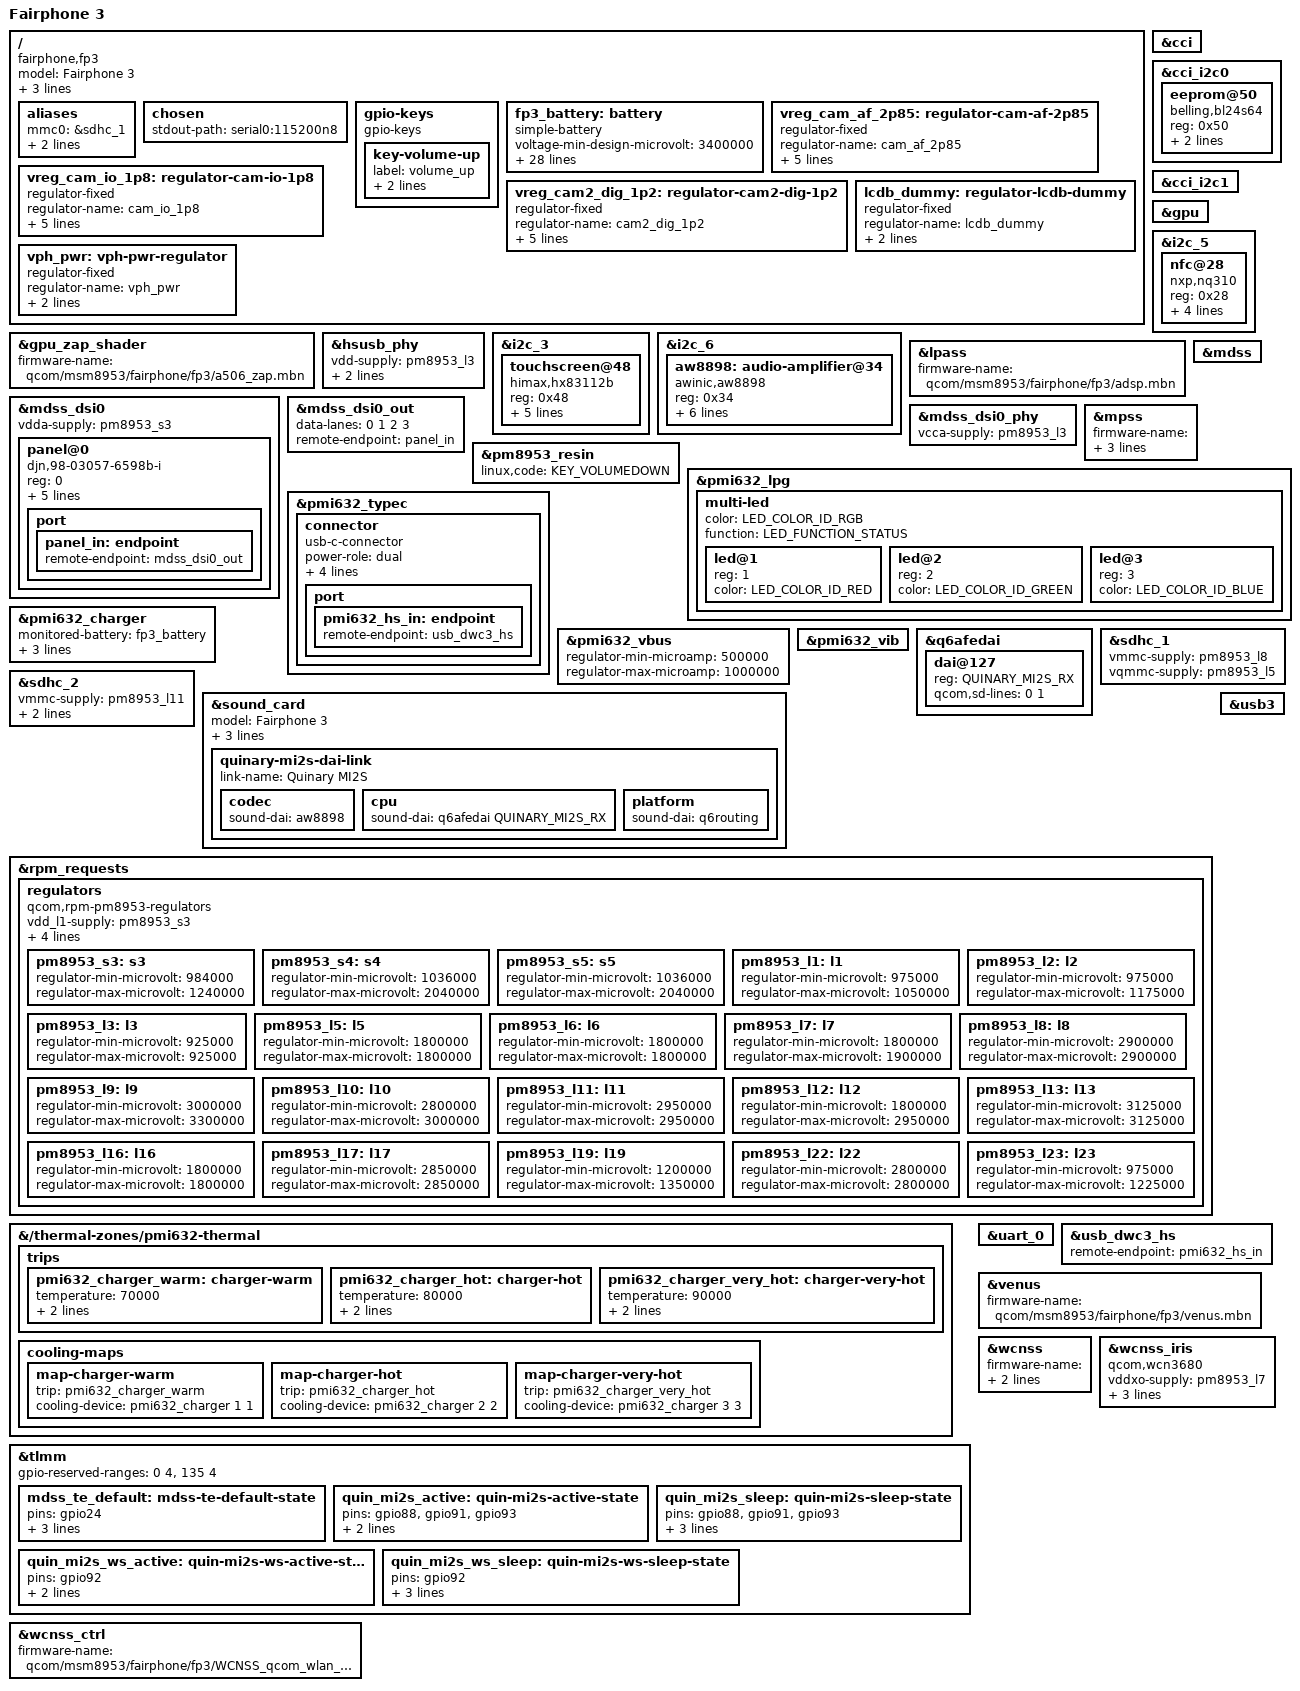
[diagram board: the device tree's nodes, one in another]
// SPDX-License-Identifier: BSD-3-Clause
/*
 * Copyright (c) 2022, Luca Weiss <luca@z3ntu.xyz>
 */
/dts-v1/;

#include <dt-bindings/leds/common.h>
#include "sdm632.dtsi"
#include "pm8953.dtsi"
#include "pmi632.dtsi"

/ {
	model = "Fairphone 3";
	compatible = "fairphone,fp3", "qcom,sdm632";
	chassis-type = "handset";
	qcom,msm-id = <349 0>;
	qcom,board-id = <8 0x10000>;

	aliases {
		mmc0 = &sdhc_1;
		mmc1 = &sdhc_2;
		serial0 = &uart_0;
	};

	chosen {
		stdout-path = "serial0:115200n8";
	};

	gpio-keys {
		compatible = "gpio-keys";

		key-volume-up {
			label = "volume_up";
			linux,code = <KEY_VOLUMEUP>;
			gpios = <&tlmm 85 GPIO_ACTIVE_LOW>;
		};
	};

	/*
	 * Battery profile from the Fairphone downstream qg-batterydata.
	 *
	 * The FP3 ships two different 3000 mAh packs, told apart at runtime by
	 * a battery-ID resistor: "Kayo" at 50 kOhm, rated 2.7 A, and "Fuji" at
	 * 10 kOhm, rated 2.0 A. A simple-battery node cannot choose, so this
	 * describes Fuji - the pack in the phone this was developed on, whose
	 * ID resistor measures 10.0 kOhm here and whose downstream stack
	 * reports batt-id 9843 and selects
	 * qg-batterydata-Fuji-3000mah-Jan22th2019-pmi632.
	 *
	 * That means the current below is the pack's full rating, not a
	 * reduction of it. On a phone fitted with the other pack the charger
	 * finds the mismatch through qcom,batt-id-ohm below and falls back to
	 * its conservative default rather than charging a 50 kOhm cell to a
	 * 10 kOhm cell's limits; describing both packs properly needs a
	 * binding for more than one monitored-battery, which does not exist.
	 */
	fp3_battery: battery {
		compatible = "simple-battery";
		voltage-min-design-microvolt = <3400000>;
		voltage-max-design-microvolt = <4390000>;
		charge-full-design-microamp-hours = <3000000>;
		constant-charge-current-max-microamp = <2000000>;
		constant-charge-voltage-max-microvolt = <4390000>;

		/*
		 * The ID resistor this pack presents, and how the charger is
		 * allowed to charge it. Both are Fairphone's characterisation
		 * of this cell, from qg-batterydata-Fuji-3000mah-Jan22th2019-
		 * pmi632: 10 kOhm ID, hard limits at 0 and 55 degC, soft limits
		 * at 15 and 45, and the jeita-fcc-ranges entries for the zones
		 * outside the soft ones. The thresholds are the raw BAT_THERM
		 * ADC codes the comparators take; verified against a phone
		 * running the vendor stack, which programs the same four.
		 *
		 * The ID matters because the FP3 also ships a second 3000 mAh
		 * pack ("Kayo", 50 kOhm) rated 2.7 A with its cool band at
		 * 20 degC. Only one battery can be described here, so the
		 * charger checks the resistor before applying any of it.
		 */
		qcom,batt-id-ohm = <10000>;
		qcom,jeita-hard-thresholds = <0x5675 0x1987>;
		qcom,jeita-soft-thresholds = <0x44ff 0x2204>;
		qcom,jeita-soft-fcc-microamp = <600000 1000000>;

		/*
		 * Voltage-based fuel gauge: OCV->capacity lookup table.
		 * Extracted from the downstream Fairphone qpnp-qg battery
		 * profile (qg-batterydata-Fuji-3000mah-Jan22th2019-pmi632,
		 * pc-temp-v1-lut, 25 degC column). Values converted from the
		 * downstream 100uV units to microvolts. This is the same OCV
		 * characterisation the downstream QG gauge uses; the mainline
		 * power-supply core interpolates capacity from it.
		 */
		ocv-capacity-celsius = <25>;
		ocv-capacity-table-0 = <4375600 100>, <4353300 98>, <4328800 96>, <4304800 94>,
			<4281100 92>, <4257500 90>, <4234200 88>, <4211000 86>,
			<4188100 84>, <4165400 82>, <4142900 80>, <4121200 78>,
			<4100700 76>, <4080700 74>, <4060200 72>, <4039500 70>,
			<4020600 68>, <4003800 66>, <3988000 64>, <3972500 62>,
			<3957300 60>, <3941900 58>, <3926800 56>, <3910400 54>,
			<3890000 52>, <3868700 50>, <3854500 48>, <3844500 46>,
			<3836800 44>, <3830600 42>, <3825500 40>, <3821400 38>,
			<3818200 36>, <3814800 34>, <3811300 32>, <3807600 30>,
			<3803700 28>, <3799500 26>, <3793600 24>, <3784200 22>,
			<3772700 20>, <3760900 18>, <3747700 16>, <3732200 14>,
			<3717500 12>, <3707900 10>, <3705400 9>, <3703200 8>,
			<3701500 7>, <3698400 6>, <3682100 5>, <3644100 4>,
			<3591600 3>, <3520900 2>, <3415500 1>, <3000000 0>;
	};

	vreg_cam_af_2p85: regulator-cam-af-2p85 {
		compatible = "regulator-fixed";
		regulator-name = "cam_af_2p85";
		regulator-min-microvolt = <2850000>;
		regulator-max-microvolt = <2850000>;

		gpio = <&tlmm 128 GPIO_ACTIVE_HIGH>;
		enable-active-high;

		vin-supply = <&vph_pwr>;
	};

	vreg_cam_io_1p8: regulator-cam-io-1p8 {
		compatible = "regulator-fixed";
		regulator-name = "cam_io_1p8";
		regulator-min-microvolt = <1800000>;
		regulator-max-microvolt = <1800000>;

		gpio = <&tlmm 130 GPIO_ACTIVE_HIGH>;
		enable-active-high;

		vin-supply = <&vph_pwr>;
	};

	vreg_cam2_dig_1p2: regulator-cam2-dig-1p2 {
		compatible = "regulator-fixed";
		regulator-name = "cam2_dig_1p2";
		regulator-min-microvolt = <1200000>;
		regulator-max-microvolt = <1200000>;

		gpio = <&tlmm 46 GPIO_ACTIVE_HIGH>;
		enable-active-high;

		vin-supply = <&vph_pwr>;
	};

	/* Dummy regulator until PMI632 has LCDB VSP/VSN support */
	lcdb_dummy: regulator-lcdb-dummy {
		compatible = "regulator-fixed";
		regulator-name = "lcdb_dummy";
		regulator-min-microvolt = <5500000>;
		regulator-max-microvolt = <5500000>;
	};

	vph_pwr: vph-pwr-regulator {
		compatible = "regulator-fixed";
		regulator-name = "vph_pwr";
		regulator-always-on;
		regulator-boot-on;
	};
};

&cci {
	status = "okay";
};

&cci_i2c0 {
	/* Sony IMX363 (rear) @ 0x10 */

	eeprom@50 {
		compatible = "belling,bl24s64", "atmel,24c64";
		reg = <0x50>;
		vcc-supply = <&vreg_cam_io_1p8>;
		read-only;
	};

	/* ON Semi LC898217 VCM @ 0x72 */
};

&cci_i2c1 {
	/* Samsung S5K4H7YX (front) @ 0x10 */
};

&gpu {
	status = "okay";
};

&gpu_zap_shader {
	firmware-name = "qcom/msm8953/fairphone/fp3/a506_zap.mbn";
};

&hsusb_phy {
	vdd-supply = <&pm8953_l3>;
	vdda-pll-supply = <&pm8953_l7>;
	vdda-phy-dpdm-supply = <&pm8953_l13>;

	status = "okay";
};

&i2c_3 {
	status = "okay";

	touchscreen@48 {
		compatible = "himax,hx83112b";
		reg = <0x48>;
		interrupt-parent = <&tlmm>;
		interrupts = <65 IRQ_TYPE_LEVEL_LOW>;
		touchscreen-size-x = <1080>;
		touchscreen-size-y = <2160>;
		reset-gpios = <&tlmm 64 GPIO_ACTIVE_LOW>;
	};
};

&i2c_5 {
	status = "okay";

	nfc@28 {
		compatible = "nxp,nq310", "nxp,nxp-nci-i2c";
		reg = <0x28>;

		interrupt-parent = <&tlmm>;
		interrupts = <17 IRQ_TYPE_LEVEL_HIGH>;

		enable-gpios = <&tlmm 16 GPIO_ACTIVE_HIGH>;
		firmware-gpios = <&tlmm 62 GPIO_ACTIVE_HIGH>;
	};
};

&i2c_6 {
	status = "okay";

	aw8898: audio-amplifier@34 {
		compatible = "awinic,aw8898";
		reg = <0x34>;

		reset-gpios = <&tlmm 21 GPIO_ACTIVE_LOW>;
		interrupts-extended = <&tlmm 20 IRQ_TYPE_LEVEL_HIGH>;

		dvdd-supply = <&pm8953_l5>;
		vddio-supply = <&pm8953_l5>;
		vdd-supply = <&vph_pwr>;

		#sound-dai-cells = <0>;
	};

	/* Fairphone 3+ only: Speaker amp TAS2557 @ 4c */
};

&lpass {
	firmware-name = "qcom/msm8953/fairphone/fp3/adsp.mbn";

	status = "okay";
};

&mdss {
	status = "okay";
};

&mdss_dsi0 {
	vdda-supply = <&pm8953_s3>;
	status = "okay";

	panel@0 {
		compatible = "djn,98-03057-6598b-i";
		reg = <0>;

		reset-gpios = <&tlmm 61 GPIO_ACTIVE_LOW>;

		iovcc-supply = <&pm8953_l6>;
		vsn-supply = <&lcdb_dummy>;
		vsp-supply = <&lcdb_dummy>;

		pinctrl-0 = <&mdss_te_default>;
		pinctrl-names = "default";

		port {
			panel_in: endpoint {
				remote-endpoint = <&mdss_dsi0_out>;
			};
		};
	};
};

&mdss_dsi0_out {
	data-lanes = <0 1 2 3>;
	remote-endpoint = <&panel_in>;
};

&mdss_dsi0_phy {
	vcca-supply = <&pm8953_l3>;
	status = "okay";
};

&mpss {
	firmware-name = "qcom/msm8953/fairphone/fp3/mba.mbn",
			"qcom/msm8953/fairphone/fp3/modem.mbn";
	pll-supply = <&pm8953_l7>;

	status = "okay";
};

&pm8953_resin {
	linux,code = <KEY_VOLUMEDOWN>;
	status = "okay";
};

&pmi632_lpg {
	status = "okay";

	multi-led {
		color = <LED_COLOR_ID_RGB>;
		function = LED_FUNCTION_STATUS;

		#address-cells = <1>;
		#size-cells = <0>;

		led@1 {
			reg = <1>;
			color = <LED_COLOR_ID_RED>;
		};

		led@2 {
			reg = <2>;
			color = <LED_COLOR_ID_GREEN>;
		};

		led@3 {
			reg = <3>;
			color = <LED_COLOR_ID_BLUE>;
		};
	};
};

&pmi632_typec {
	status = "okay";

	connector {
		compatible = "usb-c-connector";

		power-role = "dual";
		data-role = "dual";
		self-powered;

		typec-power-opmode = "default";
		pd-disable;

		port {
			pmi632_hs_in: endpoint {
				remote-endpoint = <&usb_dwc3_hs>;
			};
		};
	};
};

&pmi632_charger {
	monitored-battery = <&fp3_battery>;

	/*
	 * Which PMIC pull-up the bat_id channel switches in, so the charger can
	 * turn the divider reading back into the pack's ID resistance. It
	 * follows from the channel chosen in pmi632.dtsi, but nothing in the
	 * ADC consumer interface exposes that, so the board states it.
	 */
	qcom,batt-id-pullup-ohm = <100000>;

	/* Downstream's mitigation table, minus its repeated last entry. */
	qcom,thermal-mitigation = <2000000 1500000 1000000 500000>;

	status = "okay";
};

&pmi632_vbus {
	regulator-min-microamp = <500000>;
	regulator-max-microamp = <1000000>;
	status = "okay";
};

&pmi632_vib {
	status = "okay";
};

&q6afedai {
	dai@127 {
		reg = <QUINARY_MI2S_RX>;
		qcom,sd-lines = <0 1>;
	};
};

&sdhc_1 {
	vmmc-supply = <&pm8953_l8>;
	vqmmc-supply = <&pm8953_l5>;

	status = "okay";
};

&sdhc_2 {
	vmmc-supply = <&pm8953_l11>;
	vqmmc-supply = <&pm8953_l12>;

	cd-gpios = <&tlmm 133 GPIO_ACTIVE_LOW>;

	status = "okay";
};

&sound_card {
	model = "Fairphone 3";

	pinctrl-0 = <&quin_mi2s_active>, <&quin_mi2s_ws_active>;
	pinctrl-1 = <&quin_mi2s_sleep>, <&quin_mi2s_ws_sleep>;
	pinctrl-names = "default",
			"sleep";

	status = "okay";

	/* FP3 does not use the codec on PM8953 */
	/delete-property/ audio-routing;
	/delete-node/ primary-mi2s-dai-link;
	/delete-node/ tertiary-mi2s-dai-link;

	quinary-mi2s-dai-link {
		link-name = "Quinary MI2S";

		codec {
			sound-dai = <&aw8898>;
		};

		cpu {
			sound-dai = <&q6afedai QUINARY_MI2S_RX>;
		};

		platform {
			sound-dai = <&q6routing>;
		};
	};
};

&rpm_requests {
	regulators {
		compatible = "qcom,rpm-pm8953-regulators";

		vdd_l1-supply = <&pm8953_s3>;
		vdd_l2_l3-supply = <&pm8953_s3>;
		vdd_l4_l5_l6_l7_l16_l19-supply = <&pm8953_s4>;
		vdd_l8_l11_l12_l13_l14_l15-supply = <&vph_pwr>;
		vdd_l9_l10_l17_l18_l22-supply = <&vph_pwr>;

		pm8953_s3: s3 {
			regulator-min-microvolt = <984000>;
			regulator-max-microvolt = <1240000>;
		};

		pm8953_s4: s4 {
			regulator-min-microvolt = <1036000>;
			regulator-max-microvolt = <2040000>;
		};

		pm8953_s5: s5 {
			regulator-min-microvolt = <1036000>;
			regulator-max-microvolt = <2040000>;
		};

		pm8953_l1: l1 {
			regulator-min-microvolt = <975000>;
			regulator-max-microvolt = <1050000>;
		};

		pm8953_l2: l2 {
			regulator-min-microvolt = <975000>;
			regulator-max-microvolt = <1175000>;
		};

		pm8953_l3: l3 {
			regulator-min-microvolt = <925000>;
			regulator-max-microvolt = <925000>;
		};

		pm8953_l5: l5 {
			regulator-min-microvolt = <1800000>;
			regulator-max-microvolt = <1800000>;
		};

		pm8953_l6: l6 {
			regulator-min-microvolt = <1800000>;
			regulator-max-microvolt = <1800000>;
		};

		pm8953_l7: l7 {
			regulator-min-microvolt = <1800000>;
			regulator-max-microvolt = <1900000>;
		};

		pm8953_l8: l8 {
			regulator-min-microvolt = <2900000>;
			regulator-max-microvolt = <2900000>;
		};

		pm8953_l9: l9 {
			regulator-min-microvolt = <3000000>;
			regulator-max-microvolt = <3300000>;
		};

		pm8953_l10: l10 {
			regulator-min-microvolt = <2800000>;
			regulator-max-microvolt = <3000000>;
		};

		pm8953_l11: l11 {
			regulator-min-microvolt = <2950000>;
			regulator-max-microvolt = <2950000>;
		};

		pm8953_l12: l12 {
			regulator-min-microvolt = <1800000>;
			regulator-max-microvolt = <2950000>;
		};

		pm8953_l13: l13 {
			regulator-min-microvolt = <3125000>;
			regulator-max-microvolt = <3125000>;
		};

		pm8953_l16: l16 {
			regulator-min-microvolt = <1800000>;
			regulator-max-microvolt = <1800000>;
		};

		pm8953_l17: l17 {
			regulator-min-microvolt = <2850000>;
			regulator-max-microvolt = <2850000>;
		};

		pm8953_l19: l19 {
			regulator-min-microvolt = <1200000>;
			regulator-max-microvolt = <1350000>;
		};

		pm8953_l22: l22 {
			regulator-min-microvolt = <2800000>;
			regulator-max-microvolt = <2800000>;
		};

		pm8953_l23: l23 {
			regulator-min-microvolt = <975000>;
			regulator-max-microvolt = <1225000>;
		};
	};
};

/*
 * Throttle charging on the charger's own die temperature. Downstream calls
 * this qcom,hw-die-temp-mitigation and drives it from a userspace thermal
 * daemon; here the PMIC's temperature zone drives it directly.
 *
 * The trips are ours. The zone already ends at the PMI632's own alarms, which
 * start at 95 degC, so these sit below that with room to act: measured on this
 * board the die idles at 37 degC, and the three steps taper the charge current
 * before the hardware has to.
 */
&{/thermal-zones/pmi632-thermal} {
	trips {
		pmi632_charger_warm: charger-warm {
			temperature = <70000>;
			hysteresis = <2000>;
			type = "passive";
		};

		pmi632_charger_hot: charger-hot {
			temperature = <80000>;
			hysteresis = <2000>;
			type = "passive";
		};

		pmi632_charger_very_hot: charger-very-hot {
			temperature = <90000>;
			hysteresis = <2000>;
			type = "passive";
		};
	};

	cooling-maps {
		map-charger-warm {
			trip = <&pmi632_charger_warm>;
			cooling-device = <&pmi632_charger 1 1>;
		};

		map-charger-hot {
			trip = <&pmi632_charger_hot>;
			cooling-device = <&pmi632_charger 2 2>;
		};

		map-charger-very-hot {
			trip = <&pmi632_charger_very_hot>;
			cooling-device = <&pmi632_charger 3 3>;
		};
	};
};

&tlmm {
	/*
	 * 0-3: unused but protected by TZ
	 * 135-138: fingerprint reader (SPI)
	 */
	gpio-reserved-ranges = <0 4>, <135 4>;

	mdss_te_default: mdss-te-default-state {
		pins = "gpio24";
		function = "mdp_vsync";
		drive-strength = <2>;
		bias-pull-down;
	};

	quin_mi2s_active: quin-mi2s-active-state {
		pins = "gpio88", "gpio91", "gpio93";
		function = "pri_mi2s";
		drive-strength = <8>;
	};

	quin_mi2s_sleep: quin-mi2s-sleep-state {
		pins = "gpio88", "gpio91", "gpio93";
		function = "pri_mi2s";
		drive-strength = <2>;
		bias-pull-down;
	};

	quin_mi2s_ws_active: quin-mi2s-ws-active-state {
		pins = "gpio92";
		function = "pri_mi2s_ws";
		drive-strength = <8>;
	};

	quin_mi2s_ws_sleep: quin-mi2s-ws-sleep-state {
		pins = "gpio92";
		function = "pri_mi2s_ws";
		drive-strength = <2>;
		bias-pull-down;
	};
};

&uart_0 {
	status = "okay";
};

&usb3 {
	status = "okay";
};

&usb_dwc3_hs {
	remote-endpoint = <&pmi632_hs_in>;
};

&venus {
	firmware-name = "qcom/msm8953/fairphone/fp3/venus.mbn";

	status = "okay";
};

&wcnss {
	firmware-name = "qcom/msm8953/fairphone/fp3/wcnss.mbn";
	vddpx-supply = <&pm8953_l5>;

	status = "okay";
};

&wcnss_ctrl {
	firmware-name = "qcom/msm8953/fairphone/fp3/WCNSS_qcom_wlan_nv.bin";
};

&wcnss_iris {
	compatible = "qcom,wcn3680";

	vddxo-supply = <&pm8953_l7>;
	vddrfa-supply = <&pm8953_l19>;
	vddpa-supply = <&pm8953_l9>;
	vdddig-supply = <&pm8953_l5>;
};
